# f28p65x_ecap_regs register map
Vendor: Texas Instruments
Peripheral module from a debugger description file (folder C2000).
Address unit: 16 bits
Registers are 32-bit, read-write, no defined reset value unless marked. A register's access mark holds for its fields unless they carry their own. Offsets are as the file gives them; lines under a group give offsets from that group; [hi:lo] are bit positions; {n}, {i} and the like mark numbered series; 'fields as' and 'values as' point back to an identical list; <NAME> marks a mode.

## ECAP_REGS — ECAP Registers
0x00 TSCTR — Time-Stamp Counter
  [31:0] TSCTR — Time Stamp Counter
0x02 CTRPHS — Counter Phase Offset Value Register
  [31:0] CTRPHS — Counter phase
{0x2+2i} CAP{i} (i=1..4) — Capture {i} Register
  [31:0] CAP{i} — Capture {i}
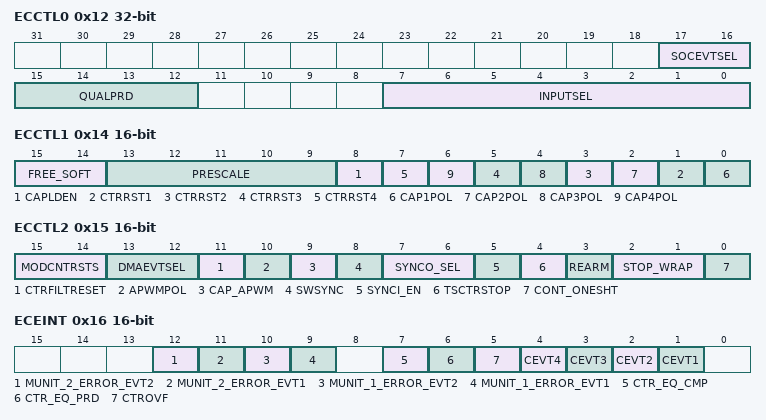
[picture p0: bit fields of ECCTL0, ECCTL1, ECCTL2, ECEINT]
0x12 ECCTL0 — Capture Control Register 0
  [17:16] SOCEVTSEL — Reserved
  [15:12] QUALPRD — Reserved
  [7:0] INPUTSEL — INPUT source select
0x14 ECCTL1 16-bit — Capture Control Register 1
  [15:14] FREE_SOFT — Emulation mode
  [13:9] PRESCALE — Event Filter prescale select
  [8] CAPLDEN — Enable Loading CAP1-4 regs on a Cap Event
  [2n-1] CTRRST{n} (n=1..4) — Counter Reset on Capture Event {n}
  [2n-2] CAP{n}POL (n=1..4) — Capture Event {n} Polarity select
0x15 ECCTL2 16-bit — Capture Control Register 2
  [15:14] MODCNTRSTS — modulo counter status
  [13:12] DMAEVTSEL — DMA event select
  [11] CTRFILTRESET — Reset event filter, modulus counter, and interrupt flags.
  [10] APWMPOL — APWM output polarity select
  [9] CAP_APWM — CAP/APWM operating mode select
  [8] SWSYNC — SW forced counter sync
  [7:6] SYNCO_SEL — Sync-out mode
  [5] SYNCI_EN — Counter sync-in select
  [4] TSCTRSTOP — TSCNT counter stop
  [3] REARM — One-shot re-arm
  [2:1] STOP_WRAP — Stop value for one-shot, Wrap for continuous
  [0] CONT_ONESHT — Continuous or one-shot
0x16 ECEINT 16-bit — Capture Interrupt Enable Register
  [12] MUNIT_2_ERROR_EVT2 — Monitoring unit 2 error event-2 interrupt enable
  [11] MUNIT_2_ERROR_EVT1 — Monitoring unit 2 error event-1 interrupt enable
  [10] MUNIT_1_ERROR_EVT2 — Monitoring unit 1 error event-2 interrupt enable
  [9] MUNIT_1_ERROR_EVT1 — Monitoring unit 1 error event-1 interrupt enable
  [7] CTR_EQ_CMP — Compare Equal Interrupt Enable
  [6] CTR_EQ_PRD — Period Equal Interrupt Enable
  [5] CTROVF — Counter Overflow Interrupt Enable
  [n] CEVT{n} (n=1..4) — Capture Event {n} Interrupt Enable
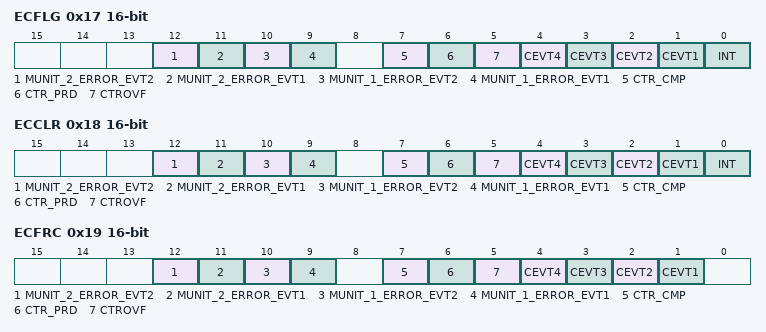
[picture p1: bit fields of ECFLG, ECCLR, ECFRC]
0x17 ECFLG 16-bit ro — Capture Interrupt Flag Register
  [12] MUNIT_2_ERROR_EVT2 — Error event 2 Interrupt Flag from monitoring unit 2
  [11] MUNIT_2_ERROR_EVT1 — Error event 2 Interrupt Flag from monitoring unit 2
  [10] MUNIT_1_ERROR_EVT2 — Error event 2 Interrupt Flag from monitoring unit 1
  [9] MUNIT_1_ERROR_EVT1 — Error event 2 Interrupt Flag from monitoring unit 1
  [7] CTR_CMP — Compare Equal Interrupt Flag
  [6] CTR_PRD — Period Equal Interrupt Flag
  [5] CTROVF — Counter Overflow Interrupt Flag
  [n] CEVT{n} (n=1..4) — Capture Event {n} Interrupt Flag
  [0] INT — Global Flag
0x18 ECCLR 16-bit — Capture Interrupt Clear Register
  [12] MUNIT_2_ERROR_EVT2 — MUNIT_2_ERROR_EVT2 interrupt flag Clear
  [11] MUNIT_2_ERROR_EVT1 — MUNIT_2_ERROR_EVT1 interrupt flag Clear
  [10] MUNIT_1_ERROR_EVT2 — MUNIT_1_ERROR_EVT2 interrupt flag Clear
  [9] MUNIT_1_ERROR_EVT1 — MUNIT_1_ERROR_EVT1 interrupt flag Clear
  [7] CTR_CMP — Compare Equal Status Clear
  [6] CTR_PRD — Period Equal Status Clear
  [5] CTROVF — Counter Overflow Status Clear
  [n] CEVT{n} (n=1..4) — Capture Event {n} Status Clear
  [0] INT — ECAP Global Interrupt Status Clear
0x19 ECFRC 16-bit — Capture Interrupt Force Register
  [12] MUNIT_2_ERROR_EVT2 — MUNIT_2_ERROR_EVT2 interrupt flag Set
  [11] MUNIT_2_ERROR_EVT1 — MUNIT_2_ERROR_EVT1 interrupt flag Set
  [10] MUNIT_1_ERROR_EVT2 — MUNIT_1_ERROR_EVT2 interrupt flag Set
  [9] MUNIT_1_ERROR_EVT1 — MUNIT_1_ERROR_EVT1 interrupt flag Set
  [7] CTR_CMP — Compare Equal Force Interrupt
  [6] CTR_PRD — Period Equal Force Interrupt
  [5] CTROVF — Counter Overflow Force Interrupt
  [n] CEVT{n} (n=1..4) — Capture Event {n} Force Interrupt
0x1E ECAPSYNCINSEL — SYNC source select register
  [6:0] SEL — SYNCIN source select
